AUTOSAR XML (schema 4-2-2)
package /STELLANTIS/EPT/ASWCs
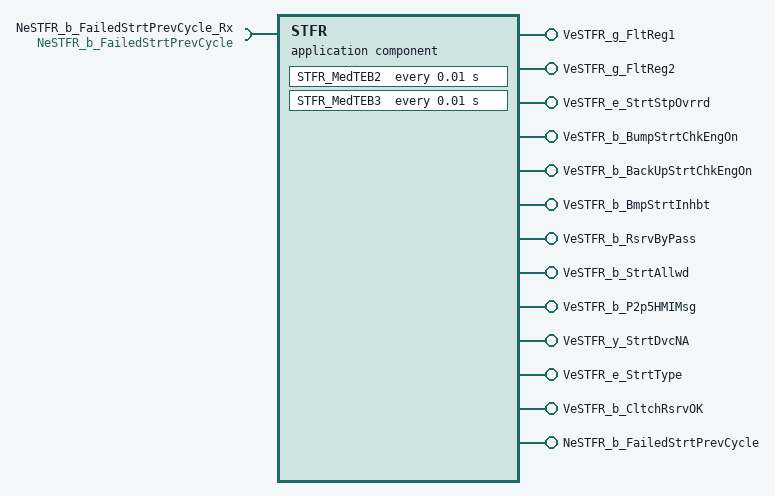
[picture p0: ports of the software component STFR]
  application sw component type STFR
    12 x provide port:
      VeSTFR_g_FltReg1: nonqueued-sender-com-spec{data-element=Value, init-value=0}, provided-interface=VeSTFR_g_FltReg1
      VeSTFR_g_FltReg2: nonqueued-sender-com-spec{data-element=Value, init-value=0}, provided-interface=VeSTFR_g_FltReg2
      VeSTFR_e_StrtStpOvrrd: nonqueued-sender-com-spec{data-element=Value, init-value=CeSTRR_e_NoOvrrd}, provided-interface=VeSTFR_e_StrtStpOvrrd
      VeSTFR_b_BumpStrtChkEngOn: nonqueued-sender-com-spec{data-element=Value, init-value=0}, provided-interface=VeSTFR_b_BumpStrtChkEngOn
      VeSTFR_b_BackUpStrtChkEngOn: nonqueued-sender-com-spec{data-element=Value, init-value=0}, provided-interface=VeSTFR_b_BackUpStrtChkEngOn
      VeSTFR_b_BmpStrtInhbt: nonqueued-sender-com-spec{data-element=Value, init-value=0}, provided-interface=VeSTFR_b_BmpStrtInhbt
      VeSTFR_b_RsrvByPass: nonqueued-sender-com-spec{data-element=Value, init-value=0}, provided-interface=VeSTFR_b_RsrvByPass
      VeSTFR_b_StrtAllwd: nonqueued-sender-com-spec{data-element=Value, init-value=0}, provided-interface=VeSTFR_b_StrtAllwd
      VeSTFR_b_P2p5HMIMsg: nonqueued-sender-com-spec{data-element=Value, init-value=0}, provided-interface=VeSTFR_b_P2p5HMIMsg
      VeSTFR_y_StrtDvcNA: nonqueued-sender-com-spec{data-element=Value, init-value=0}, provided-interface=VeSTFR_y_StrtDvcNA
      VeSTFR_e_StrtType: nonqueued-sender-com-spec{data-element=Value, init-value=CeSTRR_e_NoAction}, provided-interface=VeSTFR_e_StrtType
      VeSTFR_b_CltchRsrvOK: nonqueued-sender-com-spec{data-element=Value, init-value=0}, provided-interface=VeSTFR_b_CltchRsrvOK
    require port NeSTFR_b_FailedStrtPrevCycle_Rx: nv-require-com-spec{init-value=0, variable=NeSTFR_b_FailedStrtPrevCycle}, required-interface=NeSTFR_b_FailedStrtPrevCycle
    provide port NeSTFR_b_FailedStrtPrevCycle: nv-provide-com-spec{ram-block-init-value=0, variable=NeSTFR_b_FailedStrtPrevCycle}, provided-interface=NeSTFR_b_FailedStrtPrevCycle
    behavior IB_STFR: data-type-mapping=msADTtoIDTMapping, handle-termination-and-restart=NO-SUPPORT
      timing event Event_MedTEB2: start-on-event=STFR_MedTEB2, period=0.01
      timing event Event_MedTEB3: start-on-event=STFR_MedTEB3, period=0.01
      init event Event_STFR_ac_Init: start-on-event=STFR_ac_Init
      init event Event_PwrOn: start-on-event=STFR_PwrOn
      init event Event_PwrOff: start-on-event=STFR_PwrOff
      explicit-inter-runnable-variables:
        26 x data, all with category=VALUE, sw-calibration-access=READ-ONLY, init-value=0:
          FltReg1_write_IRV: type=UInt32
          FltReg2_write_IRV: type=UInt32
          EssOFF1_write_IRV: type=Boolean
          EssCD1_write_IRV: type=Boolean
          EssFStp1_write_IRV: type=Boolean
          TCMHMIEnbl1_write_IRV: type=Boolean
          TCMCltchAvlbl1_write_IRV: type=Boolean
          SRAREngOnRaw1_write_IRV: type=Boolean
          SRAREngOff1_write_IRV: type=Boolean
          ImpndInhbtESSOff1_write_IRV: type=Boolean
          ImpndInhbtESSOn1_write_IRV: type=Boolean
          StallDtct1_write_IRV: type=Boolean
          EFAFail1_write_IRV: type=Boolean
          STPA_EFAFail1_write_IRV: type=Boolean
          CltchStrtSpdMn1_write_IRV: type=Boolean
          EngRun1_write_IRV: type=Boolean
          EngOff1_write_IRV: type=Boolean
          InhbtTCMCndEnbl1_write_IRV: type=Boolean
          InhbtBmpStEnbl1_write_IRV: type=Boolean
          BmpStrtGrThrsh1_write_IRV: type=Boolean
          TCMEMAvlbl1_write_IRV: type=Boolean
          TCMIMAvlbl1_write_IRV: type=Boolean
          EssRun1_write_IRV: type=Boolean
          EssPFS1_write_IRV: type=Boolean
          EssInitSpn1_write_IRV: type=Boolean
          KeyOffSt1_write_IRV: type=Boolean
      5 x runnable:
        STFR_ac_Init
          data-send-points:
            access OUT_VeSTFR_e_StrtStpOvrrd_Value: accessed-variable=VeSTFR_e_StrtStpOvrrd.Value
            access OUT_VeSTFR_e_StrtType_Value: accessed-variable=VeSTFR_e_StrtType.Value
        STFR_MedTEB2
          data-send-points:
            access OUT_VeSTFR_g_FltReg1_Value: accessed-variable=VeSTFR_g_FltReg1.Value
            access OUT_VeSTFR_g_FltReg2_Value: accessed-variable=VeSTFR_g_FltReg2.Value
          written-local-variables:
            26 x access:
              WV_BmpStrtGrThrsh1_write_IRV: accessed-variable=BmpStrtGrThrsh1_write_IRV
              WV_CltchStrtSpdMn1_write_IRV: accessed-variable=CltchStrtSpdMn1_write_IRV
              WV_EFAFail1_write_IRV: accessed-variable=EFAFail1_write_IRV
              WV_EngOff1_write_IRV: accessed-variable=EngOff1_write_IRV
              WV_EngRun1_write_IRV: accessed-variable=EngRun1_write_IRV
              WV_EssCD1_write_IRV: accessed-variable=EssCD1_write_IRV
              WV_EssFStp1_write_IRV: accessed-variable=EssFStp1_write_IRV
              WV_EssInitSpn1_write_IRV: accessed-variable=EssInitSpn1_write_IRV
              WV_EssOFF1_write_IRV: accessed-variable=EssOFF1_write_IRV
              WV_EssPFS1_write_IRV: accessed-variable=EssPFS1_write_IRV
              WV_EssRun1_write_IRV: accessed-variable=EssRun1_write_IRV
              WV_FltReg1_write_IRV: accessed-variable=FltReg1_write_IRV
              WV_FltReg2_write_IRV: accessed-variable=FltReg2_write_IRV
              WV_ImpndInhbtESSOff1_write_IRV: accessed-variable=ImpndInhbtESSOff1_write_IRV
              WV_ImpndInhbtESSOn1_write_IRV: accessed-variable=ImpndInhbtESSOn1_write_IRV
              WV_InhbtBmpStEnbl1_write_IRV: accessed-variable=InhbtBmpStEnbl1_write_IRV
              WV_InhbtTCMCndEnbl1_write_IRV: accessed-variable=InhbtTCMCndEnbl1_write_IRV
              WV_KeyOffSt1_write_IRV: accessed-variable=KeyOffSt1_write_IRV
              WV_SRAREngOff1_write_IRV: accessed-variable=SRAREngOff1_write_IRV
              WV_SRAREngOnRaw1_write_IRV: accessed-variable=SRAREngOnRaw1_write_IRV
              WV_STPA_EFAFail1_write_IRV: accessed-variable=STPA_EFAFail1_write_IRV
              WV_StallDtct1_write_IRV: accessed-variable=StallDtct1_write_IRV
              WV_TCMCltchAvlbl1_write_IRV: accessed-variable=TCMCltchAvlbl1_write_IRV
              WV_TCMEMAvlbl1_write_IRV: accessed-variable=TCMEMAvlbl1_write_IRV
              WV_TCMHMIEnbl1_write_IRV: accessed-variable=TCMHMIEnbl1_write_IRV
              WV_TCMIMAvlbl1_write_IRV: accessed-variable=TCMIMAvlbl1_write_IRV
        STFR_MedTEB3
          data-send-points:
            10 x access:
              OUT_VeSTFR_e_StrtStpOvrrd_Value: accessed-variable=VeSTFR_e_StrtStpOvrrd.Value
              OUT_VeSTFR_b_BumpStrtChkEngOn_Value: accessed-variable=VeSTFR_b_BumpStrtChkEngOn.Value
              OUT_VeSTFR_b_BackUpStrtChkEngOn_Value: accessed-variable=VeSTFR_b_BackUpStrtChkEngOn.Value
              OUT_VeSTFR_b_BmpStrtInhbt_Value: accessed-variable=VeSTFR_b_BmpStrtInhbt.Value
              OUT_VeSTFR_b_RsrvByPass_Value: accessed-variable=VeSTFR_b_RsrvByPass.Value
              OUT_VeSTFR_b_StrtAllwd_Value: accessed-variable=VeSTFR_b_StrtAllwd.Value
              OUT_VeSTFR_b_P2p5HMIMsg_Value: accessed-variable=VeSTFR_b_P2p5HMIMsg.Value
              OUT_VeSTFR_y_StrtDvcNA_Value: accessed-variable=VeSTFR_y_StrtDvcNA.Value
              OUT_VeSTFR_e_StrtType_Value: accessed-variable=VeSTFR_e_StrtType.Value
              OUT_VeSTFR_b_CltchRsrvOK_Value: accessed-variable=VeSTFR_b_CltchRsrvOK.Value
        STFR_PwrOn
          data-receive-point-by-arguments:
            access IN_NeSTFR_b_FailedStrtPrevCycle_Rx_NeSTFR_b_FailedStrtPrevCycle: accessed-variable=NeSTFR_b_FailedStrtPrevCycle_Rx.NeSTFR_b_FailedStrtPrevCycle
          data-send-points:
            12 x access:
              OUT_VeSTFR_g_FltReg1_Value: accessed-variable=VeSTFR_g_FltReg1.Value
              OUT_VeSTFR_g_FltReg2_Value: accessed-variable=VeSTFR_g_FltReg2.Value
              OUT_VeSTFR_e_StrtStpOvrrd_Value: accessed-variable=VeSTFR_e_StrtStpOvrrd.Value
              OUT_VeSTFR_b_BumpStrtChkEngOn_Value: accessed-variable=VeSTFR_b_BumpStrtChkEngOn.Value
              OUT_VeSTFR_b_BackUpStrtChkEngOn_Value: accessed-variable=VeSTFR_b_BackUpStrtChkEngOn.Value
              OUT_VeSTFR_b_BmpStrtInhbt_Value: accessed-variable=VeSTFR_b_BmpStrtInhbt.Value
              OUT_VeSTFR_b_RsrvByPass_Value: accessed-variable=VeSTFR_b_RsrvByPass.Value
              OUT_VeSTFR_b_StrtAllwd_Value: accessed-variable=VeSTFR_b_StrtAllwd.Value
              OUT_VeSTFR_b_P2p5HMIMsg_Value: accessed-variable=VeSTFR_b_P2p5HMIMsg.Value
              OUT_VeSTFR_y_StrtDvcNA_Value: accessed-variable=VeSTFR_y_StrtDvcNA.Value
              OUT_VeSTFR_e_StrtType_Value: accessed-variable=VeSTFR_e_StrtType.Value
              OUT_VeSTFR_b_CltchRsrvOK_Value: accessed-variable=VeSTFR_b_CltchRsrvOK.Value
          written-local-variables:
            26 x access:
              WV_BmpStrtGrThrsh1_write_IRV: accessed-variable=BmpStrtGrThrsh1_write_IRV
              WV_CltchStrtSpdMn1_write_IRV: accessed-variable=CltchStrtSpdMn1_write_IRV
              WV_EFAFail1_write_IRV: accessed-variable=EFAFail1_write_IRV
              WV_EngOff1_write_IRV: accessed-variable=EngOff1_write_IRV
              WV_EngRun1_write_IRV: accessed-variable=EngRun1_write_IRV
              WV_EssCD1_write_IRV: accessed-variable=EssCD1_write_IRV
              WV_EssFStp1_write_IRV: accessed-variable=EssFStp1_write_IRV
              WV_EssInitSpn1_write_IRV: accessed-variable=EssInitSpn1_write_IRV
              WV_EssOFF1_write_IRV: accessed-variable=EssOFF1_write_IRV
              WV_EssPFS1_write_IRV: accessed-variable=EssPFS1_write_IRV
              WV_EssRun1_write_IRV: accessed-variable=EssRun1_write_IRV
              WV_FltReg1_write_IRV: accessed-variable=FltReg1_write_IRV
              WV_FltReg2_write_IRV: accessed-variable=FltReg2_write_IRV
              WV_ImpndInhbtESSOff1_write_IRV: accessed-variable=ImpndInhbtESSOff1_write_IRV
              WV_ImpndInhbtESSOn1_write_IRV: accessed-variable=ImpndInhbtESSOn1_write_IRV
              WV_InhbtBmpStEnbl1_write_IRV: accessed-variable=InhbtBmpStEnbl1_write_IRV
              WV_InhbtTCMCndEnbl1_write_IRV: accessed-variable=InhbtTCMCndEnbl1_write_IRV
              WV_KeyOffSt1_write_IRV: accessed-variable=KeyOffSt1_write_IRV
              WV_SRAREngOff1_write_IRV: accessed-variable=SRAREngOff1_write_IRV
              WV_SRAREngOnRaw1_write_IRV: accessed-variable=SRAREngOnRaw1_write_IRV
              WV_STPA_EFAFail1_write_IRV: accessed-variable=STPA_EFAFail1_write_IRV
              WV_StallDtct1_write_IRV: accessed-variable=StallDtct1_write_IRV
              WV_TCMCltchAvlbl1_write_IRV: accessed-variable=TCMCltchAvlbl1_write_IRV
              WV_TCMEMAvlbl1_write_IRV: accessed-variable=TCMEMAvlbl1_write_IRV
              WV_TCMHMIEnbl1_write_IRV: accessed-variable=TCMHMIEnbl1_write_IRV
              WV_TCMIMAvlbl1_write_IRV: accessed-variable=TCMIMAvlbl1_write_IRV
        STFR_PwrOff
          data-send-points:
            access OUT_NeSTFR_b_FailedStrtPrevCycle_NeSTFR_b_FailedStrtPrevCycle: accessed-variable=NeSTFR_b_FailedStrtPrevCycle.NeSTFR_b_FailedStrtPrevCycle
      4 x variation point proxy, all with category=CONDITION:
        Variant_STFR_BckupstrtEquipd: condition-access=0
        Variant_STFR_DsblFcn: condition-access=1
        Variant_STFR_P2Equipd: condition-access=0
        Variant_STFR_P2p5Equipd: condition-access=0
